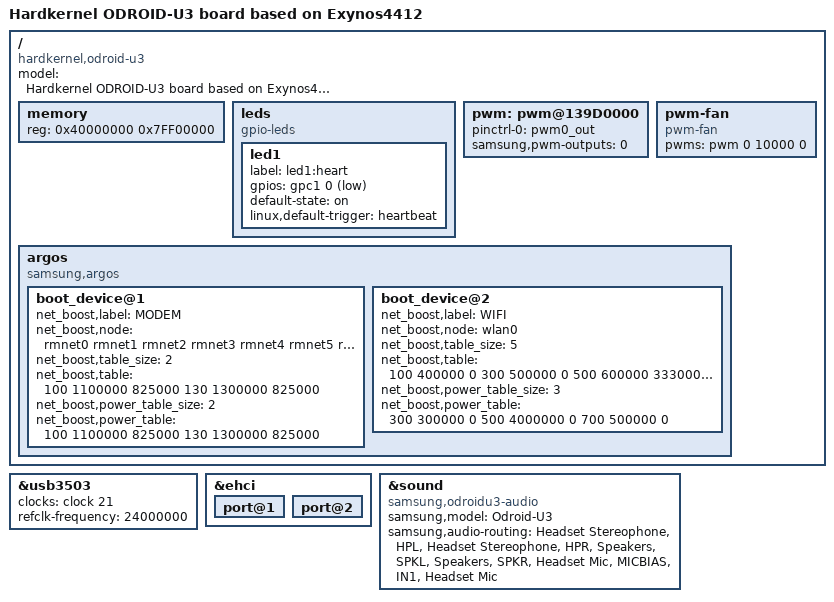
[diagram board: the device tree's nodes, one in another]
/*
 * Hardkernel's Exynos4412 based ODROID-U3 board device tree source
 *
 * Copyright (c) 2014 Marek Szyprowski <m.szyprowski@samsung.com>
 *
 * Device tree source file for Hardkernel's ODROID-U3 board which is based
 * on Samsung's Exynos4412 SoC.
 *
 * This program is free software; you can redistribute it and/or modify
 * it under the terms of the GNU General Public License version 2 as
 * published by the Free Software Foundation.
*/

/dts-v1/;
#include "exynos4412-odroid-common.dtsi"

/ {
	model = "Hardkernel ODROID-U3 board based on Exynos4412";
	compatible = "hardkernel,odroid-u3", "samsung,exynos4412", "samsung,exynos4";

	memory {
		reg = <0x40000000 0x7FF00000>;
	};

	leds {
		compatible = "gpio-leds";
		led1 {
			label = "led1:heart";
			gpios = <&gpc1 0 1>;
			default-state = "on";
			linux,default-trigger = "heartbeat";
		};
	};

	pwm: pwm@139D0000 {
		pinctrl-0 = <&pwm0_out>;
		pinctrl-names = "default";
		samsung,pwm-outputs = <0>;
		status = "okay";
	};

	pwm-fan {
		compatible = "pwm-fan";
		status = "okay";
		pwms = <&pwm 0 10000 0>;
	};

	argos {
		compatible = "samsung,argos";
		#address-cells = <1>;

		boot_device@1 {
			net_boost,label="MODEM";
			net_boost,node="rmnet0 rmnet1 rmnet2 rmnet3 rmnet4 rmnet5 rmnet6 rmnet7";
			net_boost,table_size = <2>;
			/*		 <Throughput(Mbps) CPU BUS>*/
			net_boost,table= <100 1100000 825000
					  130 1300000 825000>;
			net_boost,power_table_size = <2>;
			/*		 <Throughput(Mbps) CPU BUS>*/
			net_boost,power_table= <100 1100000 825000
					  130 1300000 825000>;
		};
		boot_device@2 {
			net_boost,label="WIFI";
			net_boost,node="wlan0";
			net_boost,table_size = <5>;
			net_boost,table= <100 400000 0
					  300 500000 0
					  500 600000 333000
					  700 800000 333000
					  900 900000 333000>;
			net_boost,power_table_size = <3>;
			net_boost,power_table= <300 300000 0
					  	500 4000000 0
					  	700 500000 0>;
		};
	};
};

&usb3503 {
	clock-names = "refclk";
	clocks = <&clock 21>;
	refclk-frequency = <24000000>;
};

&ehci {
	port@1 {
		status = "okay";
	};
	port@2 {
		status = "okay";
	};
};

&sound {
	compatible = "samsung,odroidu3-audio";
	samsung,model = "Odroid-U3";
	samsung,audio-routing =
		"Headset Stereophone", "HPL",
		"Headset Stereophone", "HPR",
		"Speakers", "SPKL",
		"Speakers", "SPKR",
		"Headset Mic", "MICBIAS",
		"IN1", "Headset Mic";
};
